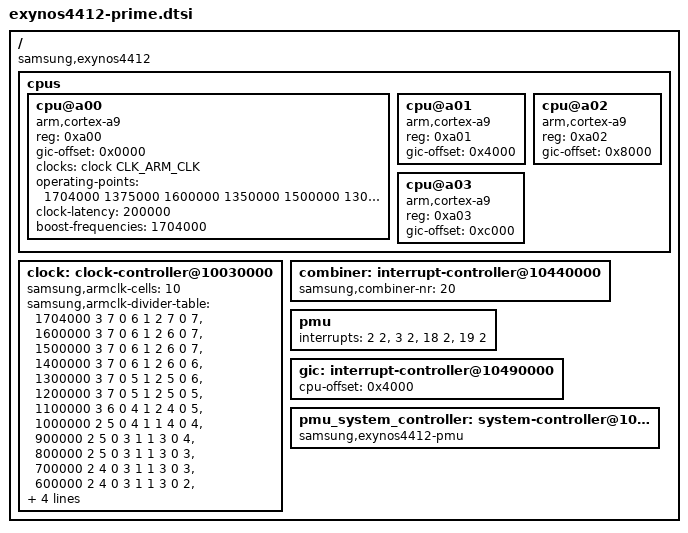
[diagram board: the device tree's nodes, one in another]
/*
 * Samsung's Exynos4412 Prime SoC device tree source
 *
 * Copyright (c) 2014 Samsung Electronics Co., Ltd.
 *		http://www.samsung.com
 *
 * Samsung's Exynos4412 Prime SoC device nodes are listed in this file. Exynos4412
 * based board files can include this file and provide values for board specfic
 * bindings.
 *
 * Note: This file does not include device nodes for all the controllers in
 * Exynos4412 Prime SoC. As device tree coverage for Exynos4412 increases,
 * additional nodes can be added to this file.
 *
 * This program is free software; you can redistribute it and/or modify
 * it under the terms of the GNU General Public License version 2 as
 * published by the Free Software Foundation.
*/

#include "exynos4x12.dtsi"

/ {
	compatible = "samsung,exynos4412", "samsung,exynos4412-prime", "samsung,exynos4";

	cpus {
		#address-cells = <1>;
		#size-cells = <0>;

		cpu@a00 {
			compatible = "arm,cortex-a9";
			device_type = "cpu";
			reg = <0xa00>;
			gic-offset = <0x0000>;

			clocks = <&clock CLK_ARM_CLK>;
			clock-names = "cpu";

			operating-points = <
				1704000 1375000
				1600000 1350000
				1500000 1300000
				1400000 1225000
				1300000 1175000
				1200000 1125000
				1100000 1075000
				1000000 1037500
				 900000 1012500
				 800000 1000000
				 700000  987500
				 600000  975000
				 500000  950000
				 400000  925000
				 300000  900000
				 200000  900000
			>;
			clock-latency = <200000>;
			boost-frequencies = <1704000>;
		};

		cpu@a01 {
			compatible = "arm,cortex-a9";
			device_type = "cpu";
			reg = <0xa01>;
			gic-offset = <0x4000>;
		};

		cpu@a02 {
			compatible = "arm,cortex-a9";
			device_type = "cpu";
			reg = <0xa02>;
			gic-offset = <0x8000>;
		};

		cpu@a03 {
			compatible = "arm,cortex-a9";
			device_type = "cpu";
			reg = <0xa03>;
			gic-offset = <0xc000>;
		};
	};

	clock: clock-controller@10030000 {
		samsung,armclk-cells = <10>;
		samsung,armclk-divider-table = <1704000 3 7 0 6 1 2 7 0 7>,
					       <1600000 3 7 0 6 1 2 6 0 7>,
					       <1500000 3 7 0 6 1 2 6 0 7>,
					       <1400000 3 7 0 6 1 2 6 0 6>,
					       <1300000 3 7 0 5 1 2 5 0 6>,
					       <1200000 3 7 0 5 1 2 5 0 5>,
					       <1100000 3 6 0 4 1 2 4 0 5>,
					       <1000000 2 5 0 4 1 1 4 0 4>,
					       < 900000 2 5 0 3 1 1 3 0 4>,
					       < 800000 2 5 0 3 1 1 3 0 3>,
					       < 700000 2 4 0 3 1 1 3 0 3>,
					       < 600000 2 4 0 3 1 1 3 0 2>,
					       < 500000 2 4 0 3 1 1 3 0 2>,
					       < 400000 2 4 0 3 1 1 3 0 1>,
					       < 300000 2 4 0 2 1 1 3 0 1>,
					       < 200000 1 3 0 1 1 1 3 0 0>;
	};

	combiner: interrupt-controller@10440000 {
		samsung,combiner-nr = <20>;
	};

	pmu {
		interrupts = <2 2>, <3 2>, <18 2>, <19 2>;
	};

	gic: interrupt-controller@10490000 {
		cpu-offset = <0x4000>;
	};

	pmu_system_controller: system-controller@10020000 {
		compatible = "samsung,exynos4412-pmu", "syscon";
	};
};
